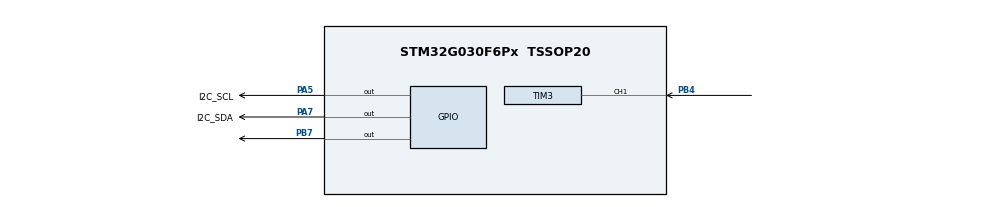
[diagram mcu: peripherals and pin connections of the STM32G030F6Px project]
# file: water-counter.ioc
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Mcu.Family=STM32G0
Mcu.Name=STM32G030F6Px
Mcu.Package=TSSOP20
NVIC.TIM3_IRQn=true\:0\:0\:false\:false\:true\:true\:true\:true
PA13.Mode=Serial_Wire
PA13.Signal=SYS_SWDIO
PA14-BOOT0.Mode=Serial_Wire
PA14-BOOT0.Signal=SYS_SWCLK
PA14-BOOT0__PA15.StandardMode=true
PA5.GPIO_Label=I2C_SCL
PA5.GPIO_ModeDefaultOutputPP=GPIO_MODE_OUTPUT_OD
PA5.GPIO_PuPd=GPIO_NOPULL
PA5.GPIO_Speed=GPIO_SPEED_FREQ_HIGH
PA5.Signal=GPIO_Output
PA7.GPIO_Label=I2C_SDA
PA7.GPIO_ModeDefaultOutputPP=GPIO_MODE_OUTPUT_OD
PA7.GPIO_PuPd=GPIO_NOPULL
PA7.GPIO_Speed=GPIO_SPEED_FREQ_HIGH
PA7.Signal=GPIO_Output
PB0__PB1__PB2__PA8.StandardMode=true
PB3__PB4__PB5__PB6.StandardMode=true
PB4.Signal=S_TIM3_CH1
PB7.Signal=GPIO_Output
PB7__PB8.StandardMode=true
PC14-OSC32_IN\ (PC14)__PB9.StandardMode=true
ProjectManager.HeapSize=0x200
ProjectManager.StackSize=0x400
ProjectManager.TargetToolchain=MDK-ARM V5.32
RCC.ADCFreq_Value=64000000
RCC.AHBFreq_Value=64000000
RCC.CortexFreq_Value=64000000
RCC.EXTERNAL_CLOCK_VALUE=12288000
RCC.HCLKFreq_Value=64000000
RCC.HSE_VALUE=8000000
RCC.HSI_VALUE=16000000
RCC.LSE_VALUE=32768
RCC.SYSCLKFreq_VALUE=64000000
RCC.SYSCLKSource=RCC_SYSCLKSOURCE_PLLCLK
RCC.VCOOutputFreq_Value=128000000
SH.S_TIM3_CH1.0=TIM3_CH1,Input_Capture1_from_TI1
SH.S_TIM3_CH1.1=TIM3_CH1,TriggerSource_TI1FP1
TIM3.AutoReloadPreload=TIM_AUTORELOAD_PRELOAD_ENABLE
TIM3.Channel-Input_Capture1_from_TI1=TIM_CHANNEL_1
TIM3.Channel-Input_Capture2_from_TI1_63=TIM_CHANNEL_2
TIM3.ICFilter_CH1=8
TIM3.ICPolarity_CH2=TIM_INPUTCHANNELPOLARITY_FALLING
TIM3.Prescaler=63
VP_TIM16_VS_ClockSourceINT.Mode=Enable_Timer
VP_TIM3_VS_ClockSourceINT.Mode=Internal
VP_TIM3_VS_ControllerModeReset.Mode=Reset Mode
VP_TIM3_VS_indirect_ch1.Mode=Input_Capture2_from_TI1_63
board=custom

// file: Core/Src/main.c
/* USER CODE BEGIN Header */
/**
  ******************************************************************************
  * @file           : main.c
  * @brief          : Main program body
  ******************************************************************************
  * @attention
  *
  * Copyright (c) 2024 STMicroelectronics.
  * All rights reserved.
  *
  * This software is licensed under terms that can be found in the LICENSE file
  * in the root directory of this software component.
  * If no LICENSE file comes with this software, it is provided AS-IS.
  *
  ******************************************************************************
  */
/* USER CODE END Header */
#include "main.h"
#include "tim.h"
#include "gpio.h"

/* USER CODE BEGIN Includes */
#include "EventRecorder.h"
#include "stdio.h"
/* USER CODE END Includes */

/* USER CODE BEGIN PV */
uint16_t PWM1_T_Count, PWM1_D_Count;
float PWM1_Duty, PWM1_Freq;
/* USER CODE END PV */

void SystemClock_Config(void);

int main(void)
{
  /* USER CODE BEGIN 1 */
	EventRecorderInitialize(EventRecordAll, 1U);
	EventRecorderStart();
  /* USER CODE END 1 */

  /* MCU Configuration--------------------------------------------------------*/

  /* Reset of all peripherals, Initializes the Flash interface and the Systick. */
  LL_APB2_GRP1_EnableClock(LL_APB2_GRP1_PERIPH_SYSCFG);
  LL_APB1_GRP1_EnableClock(LL_APB1_GRP1_PERIPH_PWR);

  /* SysTick_IRQn interrupt configuration */
  NVIC_SetPriority(SysTick_IRQn, 3);

  /* USER CODE BEGIN Init */
	printf("CPU @ %d Hz\n", SystemCoreClock);
  /* USER CODE END Init */

  /* Configure the system clock */
  SystemClock_Config();

  /* Initialize all configured peripherals */
  MX_GPIO_Init();
  MX_TIM3_Init();
  MX_TIM16_Init();
  /* USER CODE BEGIN 2 */
	LL_TIM_CC_EnableChannel(TIM3, LL_TIM_CHANNEL_CH1);
	LL_TIM_CC_EnableChannel(TIM3, LL_TIM_CHANNEL_CH2);
	LL_TIM_EnableCounter(TIM3);
	LL_TIM_EnableIT_CC1(TIM3);
	LL_TIM_EnableIT_CC2(TIM3);
  /* USER CODE END 2 */

  /* Infinite loop */
  while (1)
  {

  }
}

void SystemClock_Config(void)
{
  LL_FLASH_SetLatency(LL_FLASH_LATENCY_2);
  while(LL_FLASH_GetLatency() != LL_FLASH_LATENCY_2)
  {
  }

  /* HSI configuration and activation */
  LL_RCC_HSI_Enable();
  while(LL_RCC_HSI_IsReady() != 1)
  {
  }

  /* Main PLL configuration and activation */
  LL_RCC_PLL_ConfigDomain_SYS(LL_RCC_PLLSOURCE_HSI, LL_RCC_PLLM_DIV_1, 8, LL_RCC_PLLR_DIV_2);
  LL_RCC_PLL_Enable();
  LL_RCC_PLL_EnableDomain_SYS();
  while(LL_RCC_PLL_IsReady() != 1)
  {
  }

  /* Set AHB prescaler*/
  LL_RCC_SetAHBPrescaler(LL_RCC_SYSCLK_DIV_1);

  /* Sysclk activation on the main PLL */
  LL_RCC_SetSysClkSource(LL_RCC_SYS_CLKSOURCE_PLL);
  while(LL_RCC_GetSysClkSource() != LL_RCC_SYS_CLKSOURCE_STATUS_PLL)
  {
  }

  /* Set APB1 prescaler*/
  LL_RCC_SetAPB1Prescaler(LL_RCC_APB1_DIV_1);

  LL_Init1msTick(64000000);

  /* Update CMSIS variable (which can be updated also through SystemCoreClockUpdate function) */
  LL_SetSystemCoreClock(64000000);
}

void Error_Handler(void)
{
  __disable_irq();
  while (1)
  {
  }
}
